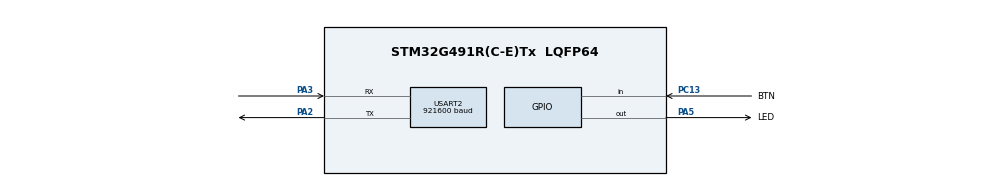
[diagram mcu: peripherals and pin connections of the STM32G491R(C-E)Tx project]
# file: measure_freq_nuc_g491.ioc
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Mcu.Family=STM32G4
Mcu.Name=STM32G491R(C-E)Tx
Mcu.Package=LQFP64
NVIC.PriorityGroup=NVIC_PRIORITYGROUP_4
PA13.GPIO_Label=T_SWDIO
PA13.Mode=Trace_Asynchronous_SW
PA13.Signal=SYS_JTMS-SWDIO
PA14.GPIO_Label=T_SWCLK
PA14.Mode=Trace_Asynchronous_SW
PA14.Signal=SYS_JTCK-SWCLK
PA2.Mode=Asynchronous
PA2.Signal=USART2_TX
PA3.Mode=Asynchronous
PA3.Signal=USART2_RX
PA5.GPIO_Label=LED
PA5.Signal=GPIO_Output
PB3.GPIO_Label=T_SWO
PB3.Mode=Trace_Asynchronous_SW
PB3.Signal=SYS_JTDO-SWO
PC13.GPIO_Label=BTN
PC13.Signal=GPIO_Input
PC14-OSC32_IN.GPIO_Label=RCC_OSC32_IN
PC14-OSC32_IN.Mode=LSE-External-Oscillator
PC14-OSC32_IN.Signal=RCC_OSC32_IN
PC15-OSC32_OUT.GPIO_Label=RCC_OSC32_OUT
PC15-OSC32_OUT.Mode=LSE-External-Oscillator
PC15-OSC32_OUT.Signal=RCC_OSC32_OUT
PF0-OSC_IN.GPIO_Label=RCC_OSC_IN
PF0-OSC_IN.Mode=HSE-External-Oscillator
PF0-OSC_IN.Signal=RCC_OSC_IN
PF1-OSC_OUT.GPIO_Label=RCC_OSC_OUT
PF1-OSC_OUT.Mode=HSE-External-Oscillator
PF1-OSC_OUT.Signal=RCC_OSC_OUT
ProjectManager.HeapSize=0x200
ProjectManager.StackSize=0x400
ProjectManager.TargetToolchain=CMake
RCC.ADC12Freq_Value=170000000
RCC.ADC345Freq_Value=170000000
RCC.AHBFreq_Value=170000000
RCC.APB1Freq_Value=170000000
RCC.APB1TimFreq_Value=170000000
RCC.APB2Freq_Value=170000000
RCC.APB2TimFreq_Value=170000000
RCC.CortexFreq_Value=170000000
RCC.EXTERNAL_CLOCK_VALUE=12288000
RCC.HCLKFreq_Value=170000000
RCC.HSE_VALUE=24000000
RCC.HSI48_VALUE=48000000
RCC.HSI_VALUE=16000000
RCC.PLLM=RCC_PLLM_DIV6
RCC.PLLN=85
RCC.PLLSourceVirtual=RCC_PLLSOURCE_HSE
RCC.RTCClockSelection=RCC_RTCCLKSOURCE_LSE
RCC.SYSCLKFreq_VALUE=170000000
RCC.SYSCLKSource=RCC_SYSCLKSOURCE_PLLCLK
RCC.USBFreq_Value=48000000
RCC.VCOOutputFreq_Value=340000000
USART2.BaudRate=921600
USART2.FIFOMode=FIFOMODE_ENABLE
USART2.VirtualMode-Asynchronous=VM_ASYNC
VP_SYS_VS_DBSignals.Mode=DisableDeadBatterySignals
board=NUCLEO-G491RE

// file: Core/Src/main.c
/* USER CODE BEGIN Header */
/**
  ******************************************************************************
  * @file           : main.c
  * @brief          : Main program body
  ******************************************************************************
  * @attention
  *
  * Copyright (c) 2026 STMicroelectronics.
  * All rights reserved.
  *
  * This software is licensed under terms that can be found in the LICENSE file
  * in the root directory of this software component.
  * If no LICENSE file comes with this software, it is provided AS-IS.
  *
  ******************************************************************************
  */
/* USER CODE END Header */
#include "main.h"
#include "usart.h"
#include "gpio.h"

/* USER CODE BEGIN Includes */
#include "freq_meas.h"

/* USER CODE END Includes */

void SystemClock_Config(void);

int main(void)
{

  /* MCU Configuration--------------------------------------------------------*/

  /* Reset of all peripherals, Initializes the Flash interface and the Systick. */
  LL_APB2_GRP1_EnableClock(LL_APB2_GRP1_PERIPH_SYSCFG);
  LL_APB1_GRP1_EnableClock(LL_APB1_GRP1_PERIPH_PWR);

  /* System interrupt init*/
  NVIC_SetPriorityGrouping(NVIC_PRIORITYGROUP_4);

  /** Disable the internal Pull-Up in Dead Battery pins of UCPD peripheral
  */
  LL_PWR_DisableUCPDDeadBattery();

  /* Configure the system clock */
  SystemClock_Config();

  /* Initialize all configured peripherals */
  MX_GPIO_Init();
  MX_USART2_UART_Init();
  /* USER CODE BEGIN 2 */
  freq_meas_init();

  /* USER CODE END 2 */

  /* Infinite loop */
  while (1)
  {

    /* USER CODE BEGIN 3 */
    freq_meas_process();
  }
  /* USER CODE END 3 */
}

void SystemClock_Config(void)
{
  LL_FLASH_SetLatency(LL_FLASH_LATENCY_4);
  while(LL_FLASH_GetLatency() != LL_FLASH_LATENCY_4)
  {
  }
  LL_PWR_EnableRange1BoostMode();
  LL_RCC_HSE_Enable();
   /* Wait till HSE is ready */
  while(LL_RCC_HSE_IsReady() != 1)
  {
  }

  LL_RCC_PLL_ConfigDomain_SYS(LL_RCC_PLLSOURCE_HSE, LL_RCC_PLLM_DIV_6, 85, LL_RCC_PLLR_DIV_2);
  LL_RCC_PLL_EnableDomain_SYS();
  LL_RCC_PLL_Enable();
   /* Wait till PLL is ready */
  while(LL_RCC_PLL_IsReady() != 1)
  {
  }

  LL_RCC_SetSysClkSource(LL_RCC_SYS_CLKSOURCE_PLL);
  LL_RCC_SetAHBPrescaler(LL_RCC_SYSCLK_DIV_2);
   /* Wait till System clock is ready */
  while(LL_RCC_GetSysClkSource() != LL_RCC_SYS_CLKSOURCE_STATUS_PLL)
  {
  }

  /* Insure 1us transition state at intermediate medium speed clock*/
  for (__IO uint32_t i = (170 >> 1); i !=0; i--);

  /* Set AHB prescaler*/
  LL_RCC_SetAHBPrescaler(LL_RCC_SYSCLK_DIV_1);
  LL_RCC_SetAPB1Prescaler(LL_RCC_APB1_DIV_1);
  LL_RCC_SetAPB2Prescaler(LL_RCC_APB2_DIV_1);

  LL_Init1msTick(170000000);

  LL_SetSystemCoreClock(170000000);
}

void Error_Handler(void)
{
  __disable_irq();
  while (1)
  {
  }
}
